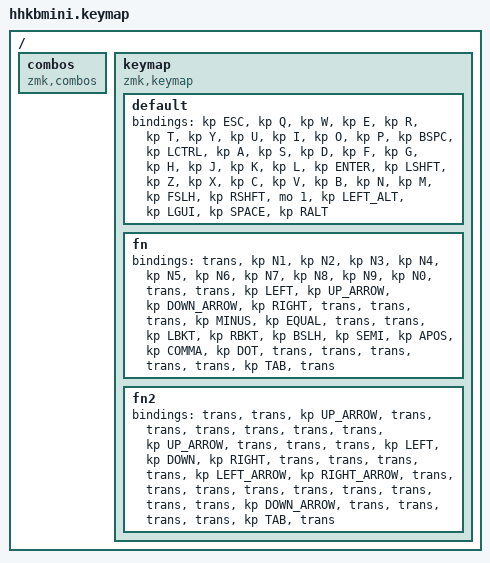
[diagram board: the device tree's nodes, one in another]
#include <behaviors.dtsi>
#include <dt-bindings/zmk/keys.h>

/ {
    combos { compatible = "zmk,combos"; };

    keymap {
        compatible = "zmk,keymap";

        default {
            bindings = <
&kp ESC  &kp Q  &kp W  &kp E  &kp R  &kp T  &kp Y  &kp U  &kp I  &kp O  &kp P  &kp BSPC  &kp LCTRL  &kp A  &kp S  &kp D  &kp F  &kp G  &kp H  &kp J  &kp K  &kp L  &kp ENTER  &kp LSHFT  &kp Z  &kp X  &kp C  &kp V  &kp B  &kp N  &kp M  &kp FSLH  &kp RSHFT  &mo 1  &kp LEFT_ALT  &kp LGUI  &kp SPACE  &kp RALT
            >;
        };

        fn {
            bindings = <
&trans  &kp N1  &kp N2  &kp N3  &kp N4  &kp N5  &kp N6  &kp N7  &kp N8  &kp N9  &kp N0  &trans  &trans  &kp LEFT  &kp UP_ARROW  &kp DOWN_ARROW  &kp RIGHT  &trans  &trans  &trans  &kp MINUS  &kp EQUAL  &trans  &trans  &kp LBKT  &kp RBKT  &kp BSLH  &kp SEMI  &kp APOS  &kp COMMA  &kp DOT  &trans  &trans  &trans  &trans  &trans  &kp TAB  &trans
            >;
        };

        fn2 {
            bindings = <
&trans  &trans  &kp UP_ARROW  &trans  &trans  &trans  &trans  &trans  &trans  &kp UP_ARROW  &trans  &trans  &trans  &kp LEFT  &kp DOWN  &kp RIGHT  &trans  &trans  &trans  &trans  &kp LEFT_ARROW  &kp RIGHT_ARROW  &trans  &trans  &trans  &trans  &trans  &trans  &trans  &trans  &trans  &kp DOWN_ARROW  &trans  &trans  &trans  &trans  &kp TAB  &trans
            >;
        };
    };
};
